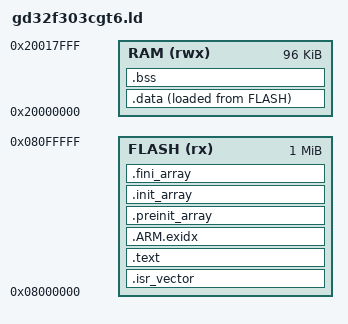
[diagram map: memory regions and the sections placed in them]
/* GD32F303CGT6 Linker Script */
MEMORY
{
  FLASH (rx) : ORIGIN = 0x08000000, LENGTH = 1024K
  RAM (rwx)  : ORIGIN = 0x20000000, LENGTH = 96K
}

ENTRY(Reset_Handler)

_sp = ORIGIN(RAM) + LENGTH(RAM);

SECTIONS
{
  .isr_vector :
  {
    KEEP(*(.vectors))
    KEEP(*(.isr_vector))
  } > FLASH

  .text :
  {
    *(.text*)
    *(.rodata*)
    *(.glue_7)
    *(.glue_7t)
    *(.eh_frame)
    KEEP(*(.init))
    KEEP(*(.fini))
    _etext = .;
  } > FLASH

  .ARM.exidx :
  {
    *(.ARM.exidx*)
    *(.gnu.linkonce.armexidx.*)
  } > FLASH

  .preinit_array :
  {
    PROVIDE_HIDDEN (__preinit_array_start = .);
    KEEP(*(.preinit_array*))
    PROVIDE_HIDDEN (__preinit_array_end = .);
  } > FLASH

  .init_array :
  {
    PROVIDE_HIDDEN (__init_array_start = .);
    KEEP(*(SORT(.init_array.*)))
    KEEP(*(.init_array*))
    PROVIDE_HIDDEN (__init_array_end = .);
  } > FLASH

  .fini_array :
  {
    PROVIDE_HIDDEN (__fini_array_start = .);
    KEEP(*(SORT(.fini_array.*)))
    KEEP(*(.fini_array*))
    PROVIDE_HIDDEN (__fini_array_end = .);
  } > FLASH

  _sidata = LOADADDR(.data);
  .data :
  {
    _sdata = .;
    *(.data*)
    _edata = .;
  } > RAM AT > FLASH

  .bss :
  {
    _sbss = .;
    *(.bss*)
    *(COMMON)
    _ebss = .;
  } > RAM

  . = ALIGN(8);
  end = .;
  _end = .;

  /DISCARD/ :
  {
    *(.note.GNU-stack)
  }
}

